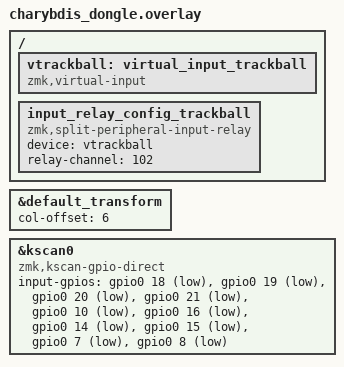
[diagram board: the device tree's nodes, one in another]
#include "charybdis.dtsi"
#include "charybdis_3610.dtsi"

&default_transform {
    col-offset = <6>;
};

&kscan0 {
    compatible = "zmk,kscan-gpio-direct";
    input-gpios = <&gpio0 18 (GPIO_ACTIVE_LOW | GPIO_PULL_UP)>,
                 <&gpio0 19 (GPIO_ACTIVE_LOW | GPIO_PULL_UP)>,
                 <&gpio0 20 (GPIO_ACTIVE_LOW | GPIO_PULL_UP)>,
                 <&gpio0 21 (GPIO_ACTIVE_LOW | GPIO_PULL_UP)>,
                 <&gpio0 10 (GPIO_ACTIVE_LOW | GPIO_PULL_UP)>,
                 <&gpio0 16 (GPIO_ACTIVE_LOW | GPIO_PULL_UP)>,
                 <&gpio0 14 (GPIO_ACTIVE_LOW | GPIO_PULL_UP)>,
                 <&gpio0 15 (GPIO_ACTIVE_LOW | GPIO_PULL_UP)>,
                 <&gpio0  7 (GPIO_ACTIVE_LOW | GPIO_PULL_UP)>,
                 <&gpio0  8 (GPIO_ACTIVE_LOW | GPIO_PULL_UP)>;
};

/ {
    vtrackball: virtual_input_trackball {
        compatible = "zmk,virtual-input";
    };
    input_relay_config_trackball {
        compatible = "zmk,split-peripheral-input-relay";
        device = <&vtrackball>;
        relay-channel = <102>;
    };
};
